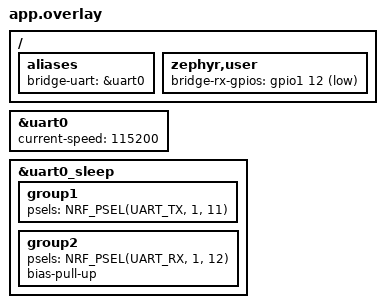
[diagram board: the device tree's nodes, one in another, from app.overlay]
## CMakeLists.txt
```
cmake_minimum_required(VERSION 3.24)

find_package(Zephyr REQUIRED HINTS $ENV{ZEPHYR_BASE})
project(TrackNodeBluetooth LANGUAGES C CXX ASM)

target_sources(app PRIVATE
    src/main.cpp
    src/infrastructure/bridge_service.cpp
    src/drivers/devices/zephyr_uart.cpp
    src/drivers/devices/zephyr_bluetooth.cpp
    src/drivers/devices/zephyr_gatt_server.cpp
    ../../src/drivers/protocols/bridge_codec.cpp
    ../../src/drivers/protocols/bridge_stream_parser.cpp
)

target_include_directories(app PRIVATE
    include
    ../../include
    ../../lib/expected/include
)
```

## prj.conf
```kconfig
CONFIG_CPP=y
CONFIG_STD_CPP20=y
CONFIG_GLIBCXX_LIBCPP=y
CONFIG_NEWLIB_LIBC=y
CONFIG_MAIN_STACK_SIZE=4096
CONFIG_SERIAL=y
CONFIG_CONSOLE=n
CONFIG_UART_CONSOLE=n
CONFIG_BOOT_BANNER=n
CONFIG_BT=y
CONFIG_BT_PERIPHERAL=y
CONFIG_BT_MAX_CONN=1
CONFIG_BT_SMP=y
CONFIG_BT_SMP_SC_PAIR_ONLY=y
CONFIG_BT_SMP_APP_PAIRING_ACCEPT=y
CONFIG_BT_SMP_ALLOW_UNAUTH_OVERWRITE=y
CONFIG_BT_BONDABLE=y
CONFIG_BT_MAX_PAIRED=8
CONFIG_BT_KEYS_OVERWRITE_OLDEST=y
CONFIG_BT_KEYS_SAVE_AGING_COUNTER_ON_PAIRING=y
CONFIG_SETTINGS=y
CONFIG_BT_SETTINGS=y
CONFIG_FLASH=y
CONFIG_FLASH_PAGE_LAYOUT=y
CONFIG_FLASH_MAP=y
CONFIG_NVS=y
CONFIG_SETTINGS_NVS=y
CONFIG_BT_L2CAP_TX_MTU=131
CONFIG_BT_BUF_ACL_RX_SIZE=135
CONFIG_BT_DEVICE_NAME_DYNAMIC=y
CONFIG_BUILD_OUTPUT_UF2=y
CONFIG_UART_USE_RUNTIME_CONFIGURE=y
CONFIG_UART_INTERRUPT_DRIVEN=y
CONFIG_GPIO=y
CONFIG_PM_DEVICE=y
```

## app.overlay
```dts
/ {
	aliases {
		bridge-uart = &uart0;
	};
};

&uart0 {
	status = "okay";
	current-speed = <115200>;
};

/ {
	zephyr,user {
		bridge-rx-gpios = <&gpio1 12 (GPIO_PULL_UP | GPIO_ACTIVE_LOW)>;
	};
};

&uart0_sleep {
	/delete-node/ group1;

	group1 {
		psels = <NRF_PSEL(UART_TX, 1, 11)>;
	};

	group2 {
		psels = <NRF_PSEL(UART_RX, 1, 12)>;
		bias-pull-up;
	};
};
```

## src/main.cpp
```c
#include "drivers/devices/zephyr_uart.h"
#include "drivers/devices/zephyr_bluetooth.h"
#include "drivers/protocols/ble_bridge.h"
#include "infrastructure/bridge_service.h"
#include "drivers/protocols/bridge_codec.h"
#include <zephyr/device.h>
#include <zephyr/devicetree.h>
#include <zephyr/drivers/gpio.h>
#include <zephyr/kernel.h>

#include <algorithm>

namespace
{
constexpr char bluetooth_name[] = "TrackNode";
constexpr std::uint32_t idle_wakeup_ms = 60000;
const gpio_dt_spec bridge_rx_wake = GPIO_DT_SPEC_GET(DT_PATH(zephyr_user), bridge_rx_gpios);

k_sem activity;
}

int main()
{
	k_sem_init(&activity, 0, 1);

	static ble::zephyr_uart transport{*DEVICE_DT_GET(DT_ALIAS(bridge_uart)), ble::uart_config{
		.baud_rate = ble_bridge::baud_rate,
		.wake_input = &bridge_rx_wake,
		.awake_hold_ms = ble_bridge::receiver_awake_hold_ms,
		.peer_sleep_after_ms = ble_bridge::peer_sleep_after_ms,
		.peer_wake_guard_ms = ble_bridge::peer_wake_guard_ms
	}};

	static ble::zephyr_bluetooth bluetooth{ble::bluetooth_config{
		.name = bluetooth_name
	}};

	static ble_bridge::bridge_codec codec;

	static ble::bridge_config bridge_config {
		.transport = transport,
		.bluetooth = bluetooth,
		.codec = codec,
		.uptime_ms = []{ return k_uptime_get_32(); },

		.write_timeout_ms = 10
	};

	static ble::bridge_service bridge{bridge_config};
	transport.set_activity_signal(&activity);
	bluetooth.set_activity_signal(&activity);

	while (true)
	{
		const auto started = bridge.start();
		if (!started)
		{
			k_msleep(1000);
			continue;
		}

		while (true)
		{
			transport.resume_if_woken();
			const auto drained = bridge.drain();
			if (!drained)
			{
				bridge.stop();
				k_msleep(1000);
				break;
			}
			if (*drained)
			{
				continue;
			}

			(void)transport.suspend_when_idle();
			const auto wake_in_ms = std::min(bridge.next_wakeup_ms().value_or(idle_wakeup_ms),
				transport.suspend_after_ms().value_or(idle_wakeup_ms));
			(void)k_sem_take(&activity, K_MSEC(wake_in_ms));
		}
	}
}
```
